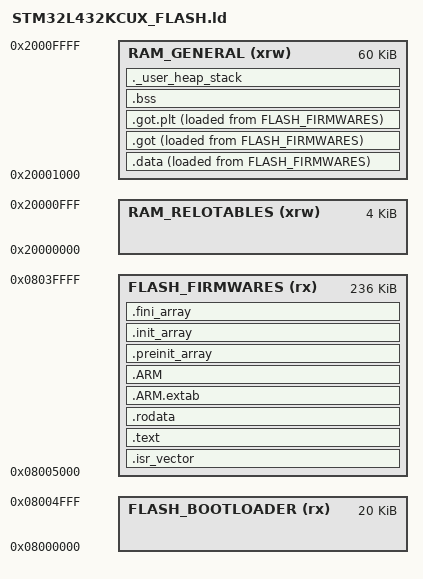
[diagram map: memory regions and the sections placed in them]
/**
 ******************************************************************************
 * @file      LinkerScript.ld
 * @author    Auto-generated by STM32CubeIDE
 *  Abstract    : Linker script for NUCLEO-L432KC Board embedding STM32L432KCUx Device from stm32l4 series
 *                      256Kbytes FLASH
 *                      64Kbytes RAM
 *
 *            Set heap size, stack size and stack location according
 *            to application requirements.
 *
 *            Set memory bank area and size if external memory is used
 ******************************************************************************
 * @attention
 *
 * <h2><center>&copy; Copyright (c) 2020 STMicroelectronics.
 * All rights reserved.</center></h2>
 *
 * This software component is licensed by ST under BSD 3-Clause license,
 * the "License"; You may not use this file except in compliance with the
 * License. You may obtain a copy of the License at:
 *                        opensource.org/licenses/BSD-3-Clause
 *
 ******************************************************************************
 */

/* Entry Point */
ENTRY(Reset_Handler)

/* Highest address of the user mode stack */
_estack = ORIGIN(RAM_GENERAL) + LENGTH(RAM_GENERAL);

_Min_Heap_Size = 0x200 ;	/* required amount of heap  */
_Min_Stack_Size = 0x400 ;	/* required amount of stack */


/* We have 256k flash and 64k ram.*/
/* General layout of the chip */
RAM_FULL_START =  0x20000000 ;
FLASH_FULL_START = 0x8000000 ;

/* Our partitioning */
RAM_FULL_LENGTH = 64K ;
RAM_RELOTABLES_LENGTH = 4K ; /* Just a guess. */
FLASH_FULL_LENGTH = 256K ;
FLASH_BOOTLOADER_LENGTH = 20K ;

/* Memories definition */
MEMORY
{
  RAM_RELOTABLES   (xrw)  : ORIGIN = RAM_FULL_START,   LENGTH = RAM_RELOTABLES_LENGTH
  RAM_GENERAL      (xrw)  : ORIGIN = ORIGIN(RAM_RELOTABLES) + LENGTH(RAM_RELOTABLES), LENGTH = RAM_FULL_LENGTH - LENGTH(RAM_RELOTABLES)
  FLASH_BOOTLOADER  (rx)  : ORIGIN = FLASH_FULL_START,   LENGTH = FLASH_BOOTLOADER_LENGTH
  FLASH_FIRMWARES   (rx)  : ORIGIN = ORIGIN(FLASH_BOOTLOADER) + LENGTH(FLASH_BOOTLOADER) , LENGTH = FLASH_FULL_LENGTH - LENGTH(FLASH_BOOTLOADER)
}

/* Sections */
SECTIONS
{
  .isr_vector :
  {
    . = ALIGN(4);
    KEEP(*(.isr_vector)) /* Startup code */
    . = ALIGN(4);
  } >FLASH_FIRMWARES

  /* The program code and other data into "FLASH" Rom type memory */
  .text :
  {
    . = ALIGN(4);
    *(.text)           /* .text sections (code) */
    *(.text*)          /* .text* sections (code) */
    *(.glue_7)         /* glue arm to thumb code */
    *(.glue_7t)        /* glue thumb to arm code */
    *(.eh_frame)

    KEEP (*(.init))
    KEEP (*(.fini))

    . = ALIGN(4);
    _etext = .;        /* define a global symbols at end of code */
  } >FLASH_FIRMWARES

  /* Constant data into "FLASH" Rom type memory */
  .rodata :
  {
    . = ALIGN(4);
    *(.rodata)         /* .rodata sections (constants, strings, etc.) */
    *(.rodata*)        /* .rodata* sections (constants, strings, etc.) */
    . = ALIGN(4);
  } >FLASH_FIRMWARES

  .ARM.extab   : {
    . = ALIGN(4);
    *(.ARM.extab* .gnu.linkonce.armextab.*)
    . = ALIGN(4);
  } >FLASH_FIRMWARES

  .ARM : {
    . = ALIGN(4);
    __exidx_start = .;
    *(.ARM.exidx*)
    __exidx_end = .;
    . = ALIGN(4);
  } >FLASH_FIRMWARES

  .preinit_array     :
  {
    . = ALIGN(4);
    PROVIDE_HIDDEN (__preinit_array_start = .);
    KEEP (*(.preinit_array*))
    PROVIDE_HIDDEN (__preinit_array_end = .);
    . = ALIGN(4);
  } >FLASH_FIRMWARES

  .init_array :
  {
    . = ALIGN(4);
    PROVIDE_HIDDEN (__init_array_start = .);
    KEEP (*(SORT(.init_array.*)))
    KEEP (*(.init_array*))
    PROVIDE_HIDDEN (__init_array_end = .);
    . = ALIGN(4);
  } >FLASH_FIRMWARES

  .fini_array :
  {
    . = ALIGN(4);
    PROVIDE_HIDDEN (__fini_array_start = .);
    KEEP (*(SORT(.fini_array.*)))
    KEEP (*(.fini_array*))
    PROVIDE_HIDDEN (__fini_array_end = .);
    . = ALIGN(4);
  } >FLASH_FIRMWARES

  /* Used by the startup to initialize data */
  _sidata = LOADADDR(.data);

  /* Initialized data sections into "RAM" Ram type memory */
  .data :
  {
    . = ALIGN(4);
    _sdata = .;        /* create a global symbol at data start */
    *(.data)           /* .data sections */
    *(.data*)          /* .data* sections */
    *(.RamFunc)        /* .RamFunc sections */
    *(.RamFunc*)       /* .RamFunc* sections */

    . = ALIGN(4);
    _edata = .;        /* define a global symbol at data end */

  } >RAM_GENERAL AT> FLASH_FIRMWARES

	/* GOT sections taken from https://github.com/rgujju/STM32-projects/blob/master/got_plt/stm32_linker.ld */
  .got :
  {
    . = ALIGN(4);
    _sgot = .;
    *(.got)
  } >RAM_GENERAL AT> FLASH_FIRMWARES
    
  .got.plt :
  {
    . = ALIGN(4);
    *(.got.plt)
    _edata = .;
  } >RAM_GENERAL AT> FLASH_FIRMWARES

  /* Uninitialized data section into "RAM" Ram type memory */
  . = ALIGN(4);
  .bss :
  {
    /* This is used by the startup in order to initialize the .bss section */
    _sbss = .;         /* define a global symbol at bss start */
    __bss_start__ = _sbss;
    *(.bss)
    *(.bss*)
    *(COMMON)

    . = ALIGN(4);
    _ebss = .;         /* define a global symbol at bss end */
    __bss_end__ = _ebss;
  } >RAM_GENERAL

  /* User_heap_stack section, used to check that there is enough "RAM" Ram  type memory left */
  ._user_heap_stack :
  {
    . = ALIGN(8);
    PROVIDE ( end = . );
    PROVIDE ( _end = . );
    . = . + _Min_Heap_Size;
    . = . + _Min_Stack_Size;
    . = ALIGN(8);
  } >RAM_GENERAL

  /* Remove information from the compiler libraries */
  /DISCARD/ :
  {
    libc.a ( * )
    libm.a ( * )
    libgcc.a ( * )
  }

  .ARM.attributes 0 : { *(.ARM.attributes) }
}
